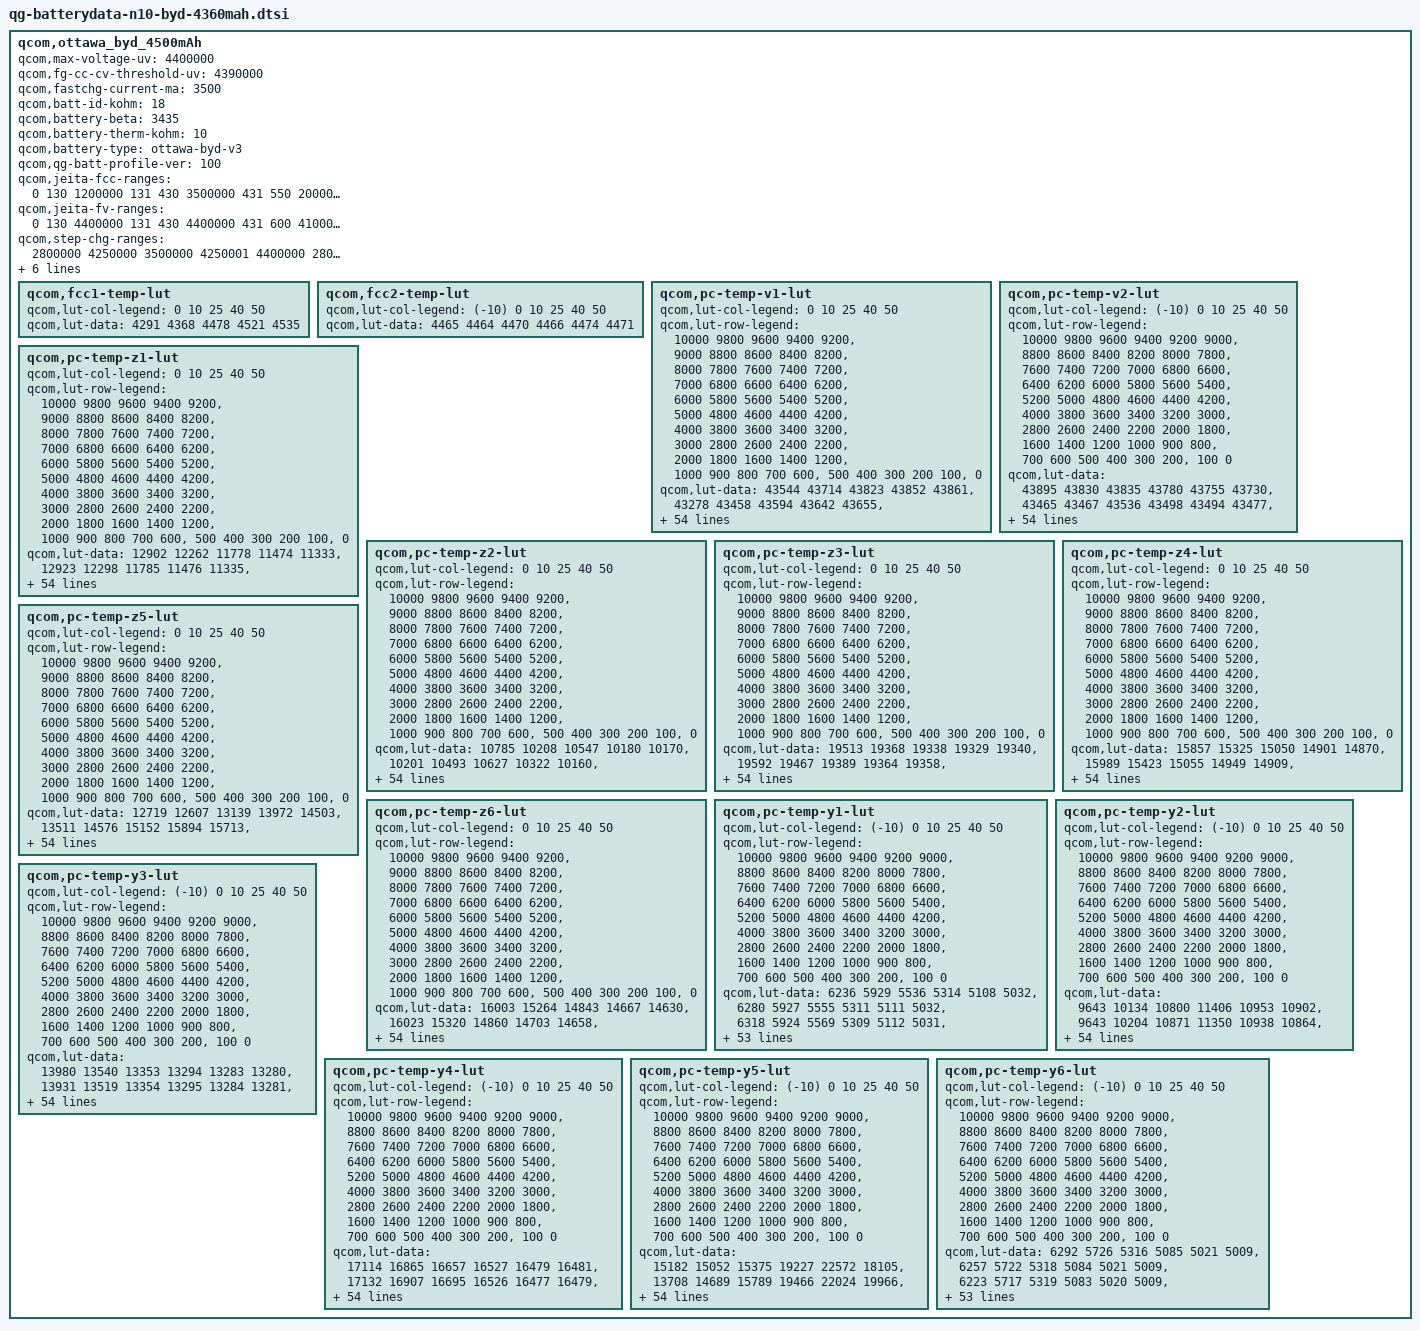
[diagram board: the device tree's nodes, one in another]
/*
 * Copyright (c) 2018, The Linux Foundation. All rights reserved.
 *
 * This program is free software; you can redistribute it and/or modify
 * it under the terms of the GNU General Public License version 2 and
 * only version 2 as published by the Free Software Foundation.
 *
 * This program is distributed in the hope that it will be useful,
 * but WITHOUT ANY WARRANTY; without even the implied warranty of
 * MERCHANTABILITY or FITNESS FOR A PARTICULAR PURPOSE.  See the
 * GNU General Public License for more details.
 */

qcom,ottawa_byd_4500mAh {
	/* 4363603_TCL_T1_Pro_4500mAH_PM6150_averaged_MasterSlave_Mar2th2020 */
	qcom,max-voltage-uv = <4400000>;
	qcom,fg-cc-cv-threshold-uv = <4390000>;
	qcom,fastchg-current-ma = <3500>;
	qcom,batt-id-kohm = <18>;
	qcom,battery-beta = <3435>;
	qcom,battery-therm-kohm = <10>;
	qcom,battery-type = "ottawa-byd-v3";
	qcom,qg-batt-profile-ver = <100>;

	qcom,jeita-fcc-ranges = <0  130   1200000
				131  430  3500000
				431 550   2000000
				551 600   0>;
	qcom,jeita-fv-ranges = <0   130   4400000
				131  430  4400000
				431  600  4100000>;
	qcom,step-chg-ranges = <2800000  4250000  3500000
				4250001  4400000  2800000>;
	qcom,ocv-based-step-chg;

	/* COOL = 10 DegC, WARM = 45 DegC */
	qcom,jeita-soft-thresholds = <0x2aee 0xfb3>;
	/* COLD = 0 DegC, HOT = 55 DegC */
	qcom,jeita-hard-thresholds = <0x3733 0xbc2>;
	/* COOL hys = 13 DegC, WARM hys = 42 DegC */
	qcom,jeita-soft-hys-thresholds = <0x279a 0x1124>;

	qcom,jeita-soft-fcc-ua = <2000000 2000000>;
	qcom,jeita-soft-fv-uv = <4100000 4100000>;

	qcom,fcc1-temp-lut {
		qcom,lut-col-legend = <0 10 25 40 50>;
		qcom,lut-data = <4291 4368 4478 4521 4535>;
	};

	qcom,fcc2-temp-lut {
		qcom,lut-col-legend = <(-10) 0 10 25 40 50>;
		qcom,lut-data = <4465 4464 4470 4466 4474 4471>;
	};

	qcom,pc-temp-v1-lut {
		qcom,lut-col-legend = <0 10 25 40 50>;
		qcom,lut-row-legend = <10000 9800 9600 9400 9200>,
			<9000 8800 8600 8400 8200>,
			<8000 7800 7600 7400 7200>,
			<7000 6800 6600 6400 6200>,
			<6000 5800 5600 5400 5200>,
			<5000 4800 4600 4400 4200>,
			<4000 3800 3600 3400 3200>,
			<3000 2800 2600 2400 2200>,
			<2000 1800 1600 1400 1200>,
			<1000 900 800 700 600>,
			<500 400 300 200 100>,
			<0>;
		qcom,lut-data = <43544 43714 43823 43852 43861>,
			<43278 43458 43594 43642 43655>,
			<43027 43209 43362 43421 43436>,
			<42788 42966 43125 43194 43213>,
			<42558 42728 42887 42959 42982>,
			<42335 42492 42648 42721 42747>,
			<42118 42263 42411 42485 42510>,
			<41906 42043 42175 42248 42272>,
			<41701 41830 41946 42014 42038>,
			<41505 41622 41720 41782 41807>,
			<41319 41418 41500 41552 41579>,
			<41130 41220 41288 41326 41353>,
			<40928 41029 41082 41104 41130>,
			<40703 40844 40881 40895 40914>,
			<40432 40634 40677 40697 40704>,
			<40136 40352 40463 40503 40501>,
			<39918 40062 40226 40303 40306>,
			<39785 39886 40006 40105 40119>,
			<39681 39782 39851 39929 39943>,
			<39573 39678 39733 39781 39789>,
			<39465 39538 39587 39621 39626>,
			<39351 39371 39347 39382 39397>,
			<39218 39179 39084 39096 39114>,
			<39072 38929 38900 38898 38912>,
			<38926 38711 38755 38774 38792>,
			<38780 38604 38643 38673 38691>,
			<38649 38535 38559 38577 38578>,
			<38552 38477 38489 38489 38467>,
			<38471 38425 38421 38404 38371>,
			<38409 38380 38356 38319 38290>,
			<38366 38339 38296 38242 38218>,
			<38332 38301 38239 38175 38154>,
			<38302 38265 38186 38115 38097>,
			<38275 38232 38137 38059 38038>,
			<38251 38200 38092 38007 37979>,
			<38224 38167 38049 37957 37920>,
			<38197 38134 38009 37909 37863>,
			<38161 38094 37968 37862 37806>,
			<38100 38030 37907 37795 37732>,
			<38018 37941 37820 37700 37630>,
			<37918 37840 37719 37593 37516>,
			<37789 37718 37607 37486 37406>,
			<37652 37578 37477 37364 37284>,
			<37504 37413 37310 37199 37119>,
			<37379 37265 37170 37066 36995>,
			<37279 37171 37075 36987 36926>,
			<37241 37145 37046 36957 36896>,
			<37212 37127 37030 36939 36877>,
			<37181 37102 37014 36919 36855>,
			<37130 37062 36969 36867 36797>,
			<36938 36861 36753 36622 36527>,
			<36510 36428 36317 36188 36091>,
			<35940 35859 35745 35616 35519>,
			<35174 35083 34971 34838 34738>,
			<33961 33854 33748 33625 33515>,
			<30000 30000 30000 30000 30000>;
	};

	qcom,pc-temp-v2-lut {
		qcom,lut-col-legend = <(-10) 0 10 25 40 50>;
		qcom,lut-row-legend = <10000 9800 9600 9400 9200 9000>,
			<8800 8600 8400 8200 8000 7800>,
			<7600 7400 7200 7000 6800 6600>,
			<6400 6200 6000 5800 5600 5400>,
			<5200 5000 4800 4600 4400 4200>,
			<4000 3800 3600 3400 3200 3000>,
			<2800 2600 2400 2200 2000 1800>,
			<1600 1400 1200 1000 900 800>,
			<700 600 500 400 300 200>,
			<100 0>;
		qcom,lut-data = <43895 43830 43835 43780 43755 43730>,
			<43465 43467 43536 43498 43494 43477>,
			<43080 43133 43252 43228 43238 43229>,
			<42748 42832 42984 42970 42990 42986>,
			<42459 42557 42733 42725 42748 42749>,
			<42198 42307 42487 42484 42508 42512>,
			<41957 42093 42240 42246 42270 42275>,
			<41736 41892 41999 42010 42033 42038>,
			<41531 41648 41772 41779 41800 41805>,
			<41333 41328 41558 41552 41570 41572>,
			<41177 41110 41350 41331 41343 41345>,
			<41089 41059 41154 41122 41124 41125>,
			<41016 41029 40960 40917 40908 40910>,
			<40821 40903 40740 40702 40699 40701>,
			<40220 40372 40482 40470 40491 40495>,
			<39670 39872 40229 40247 40292 40297>,
			<39456 39686 40013 40047 40103 40106>,
			<39313 39563 39814 39864 39924 39924>,
			<39146 39404 39619 39704 39753 39752>,
			<38945 39191 39428 39575 39600 39597>,
			<38758 38969 39236 39431 39431 39429>,
			<38606 38753 39033 39207 39202 39203>,
			<38476 38544 38831 38931 38944 38948>,
			<38377 38391 38661 38726 38748 38751>,
			<38302 38282 38520 38579 38600 38602>,
			<38237 38198 38392 38456 38475 38476>,
			<38174 38135 38266 38348 38364 38362>,
			<38115 38085 38147 38252 38264 38261>,
			<38059 38037 38055 38164 38175 38170>,
			<38007 37993 37984 38080 38095 38089>,
			<37955 37950 37929 38004 38023 38017>,
			<37902 37909 37889 37935 37959 37951>,
			<37849 37868 37858 37872 37903 37891>,
			<37793 37825 37826 37816 37839 37826>,
			<37737 37781 37794 37770 37768 37755>,
			<37678 37734 37759 37725 37692 37676>,
			<37614 37683 37721 37672 37610 37580>,
			<37545 37628 37678 37614 37525 37471>,
			<37472 37565 37623 37546 37442 37375>,
			<37393 37489 37544 37469 37364 37297>,
			<37312 37399 37446 37381 37282 37220>,
			<37236 37288 37329 37278 37186 37125>,
			<37164 37160 37190 37157 37074 37011>,
			<37095 37039 37038 37027 36948 36887>,
			<37027 36933 36904 36912 36845 36791>,
			<36950 36864 36836 36856 36801 36749>,
			<36904 36834 36813 36836 36790 36737>,
			<36847 36798 36788 36817 36772 36720>,
			<36771 36750 36747 36789 36742 36688>,
			<36657 36651 36667 36718 36655 36586>,
			<36429 36417 36439 36458 36338 36238>,
			<36030 35978 35970 35987 35840 35737>,
			<35442 35346 35332 35368 35192 35073>,
			<34582 34448 34451 34531 34306 34168>,
			<33177 33014 33092 33262 33030 32907>,
			<28802 27992 27897 27933 28022 27983>;
	};

	qcom,pc-temp-z1-lut {
		qcom,lut-col-legend = <0 10 25 40 50>;
		qcom,lut-row-legend = <10000 9800 9600 9400 9200>,
			<9000 8800 8600 8400 8200>,
			<8000 7800 7600 7400 7200>,
			<7000 6800 6600 6400 6200>,
			<6000 5800 5600 5400 5200>,
			<5000 4800 4600 4400 4200>,
			<4000 3800 3600 3400 3200>,
			<3000 2800 2600 2400 2200>,
			<2000 1800 1600 1400 1200>,
			<1000 900 800 700 600>,
			<500 400 300 200 100>,
			<0>;
		qcom,lut-data = <12902 12262 11778 11474 11333>,
			<12923 12298 11785 11476 11335>,
			<12915 12291 11783 11470 11331>,
			<12899 12278 11772 11461 11325>,
			<12880 12267 11758 11447 11315>,
			<12864 12248 11747 11433 11306>,
			<12853 12225 11736 11421 11298>,
			<12841 12207 11724 11409 11291>,
			<12834 12192 11711 11400 11285>,
			<12833 12184 11698 11393 11282>,
			<12834 12180 11692 11389 11280>,
			<12831 12177 11692 11390 11278>,
			<12802 12165 11691 11391 11277>,
			<12754 12139 11686 11391 11275>,
			<12709 12124 11673 11382 11274>,
			<12669 12124 11666 11374 11273>,
			<12654 12126 11665 11373 11273>,
			<12666 12126 11666 11374 11274>,
			<12688 12132 11667 11376 11275>,
			<12702 12140 11674 11379 11276>,
			<12710 12147 11680 11381 11277>,
			<12718 12156 11685 11383 11278>,
			<12733 12159 11690 11385 11278>,
			<12751 12157 11694 11387 11280>,
			<12756 12156 11699 11390 11281>,
			<12750 12163 11703 11392 11283>,
			<12744 12177 11708 11396 11286>,
			<12748 12183 11712 11401 11290>,
			<12761 12182 11719 11406 11294>,
			<12769 12179 11726 11411 11297>,
			<12768 12181 11732 11417 11301>,
			<12767 12191 11737 11422 11306>,
			<12772 12197 11740 11428 11310>,
			<12787 12199 11744 11434 11316>,
			<12804 12201 11748 11440 11321>,
			<12814 12206 11752 11447 11327>,
			<12825 12216 11759 11454 11332>,
			<12833 12226 11767 11461 11337>,
			<12838 12233 11774 11467 11343>,
			<12842 12240 11780 11473 11348>,
			<12850 12248 11785 11479 11353>,
			<12872 12257 11792 11488 11359>,
			<12900 12267 11801 11498 11364>,
			<12933 12277 11819 11502 11368>,
			<12953 12303 11826 11507 11373>,
			<12941 12312 11825 11512 11375>,
			<12936 12307 11822 11515 11374>,
			<12943 12311 11835 11516 11375>,
			<12917 12310 11834 11520 11379>,
			<12922 12311 11829 11529 11386>,
			<12945 12325 11850 11536 11395>,
			<12969 12340 11861 11543 11403>,
			<13024 12377 11867 11559 11414>,
			<13078 12420 11901 11579 11428>,
			<13078 12420 11901 11579 11428>,
			<13078 12420 11901 11579 11428>;
	};

	qcom,pc-temp-z2-lut {
		qcom,lut-col-legend = <0 10 25 40 50>;
		qcom,lut-row-legend = <10000 9800 9600 9400 9200>,
			<9000 8800 8600 8400 8200>,
			<8000 7800 7600 7400 7200>,
			<7000 6800 6600 6400 6200>,
			<6000 5800 5600 5400 5200>,
			<5000 4800 4600 4400 4200>,
			<4000 3800 3600 3400 3200>,
			<3000 2800 2600 2400 2200>,
			<2000 1800 1600 1400 1200>,
			<1000 900 800 700 600>,
			<500 400 300 200 100>,
			<0>;
		qcom,lut-data = <10785 10208 10547 10180 10170>,
			<10201 10493 10627 10322 10160>,
			<10245 10526 10660 10413 10269>,
			<10269 10518 10640 10439 10308>,
			<10270 10499 10567 10409 10274>,
			<10272 10458 10499 10370 10233>,
			<10281 10416 10453 10332 10216>,
			<10288 10387 10416 10282 10201>,
			<10292 10363 10390 10245 10179>,
			<10288 10347 10372 10229 10131>,
			<10276 10335 10367 10226 10080>,
			<10284 10328 10374 10240 10045>,
			<10342 10427 10379 10258 10014>,
			<10375 10815 10378 10253 10002>,
			<10324 11057 10390 10177 10018>,
			<10243 10853 10401 10105 10042>,
			<10213 10517 10400 10098 10059>,
			<10205 10430 10392 10101 10075>,
			<10197 10431 10387 10108 10090>,
			<10195 10435 10394 10130 10103>,
			<10203 10471 10421 10169 10120>,
			<10215 10535 10554 10321 10202>,
			<10239 10556 10695 10556 10340>,
			<10277 10543 10669 10588 10365>,
			<10307 10529 10527 10361 10270>,
			<10327 10538 10454 10182 10194>,
			<10344 10567 10457 10188 10428>,
			<10359 10584 10463 10226 10977>,
			<10374 10587 10481 10296 11141>,
			<10386 10587 10525 10494 10874>,
			<10391 10588 10566 10641 10543>,
			<10395 10594 10605 10595 10307>,
			<10396 10600 10640 10476 10106>,
			<10398 10605 10643 10378 10052>,
			<10400 10610 10626 10288 10049>,
			<10405 10617 10616 10239 10049>,
			<10415 10624 10620 10244 10073>,
			<10427 10634 10632 10261 10133>,
			<10446 10654 10658 10296 10192>,
			<10465 10683 10723 10396 10257>,
			<10471 10697 10761 10465 10298>,
			<10472 10697 10750 10427 10304>,
			<10417 10696 10740 10381 10309>,
			<10193 10696 10747 10494 10367>,
			<11963 10818 10738 10486 10352>,
			<11905 10826 10747 10403 10281>,
			<12046 10807 10722 10400 10260>,
			<12088 10820 10692 10416 10278>,
			<11990 10816 10639 10419 10297>,
			<12129 10877 10680 10504 10406>,
			<11455 10917 10705 10450 10302>,
			<10891 10899 10678 10275 10092>,
			<10730 10690 10632 10206 10033>,
			<9900 10598 10515 10168 9987>,
			<9900 10598 10515 10168 9987>,
			<9900 10598 10515 10168 9987>;
	};

	qcom,pc-temp-z3-lut {
		qcom,lut-col-legend = <0 10 25 40 50>;
		qcom,lut-row-legend = <10000 9800 9600 9400 9200>,
			<9000 8800 8600 8400 8200>,
			<8000 7800 7600 7400 7200>,
			<7000 6800 6600 6400 6200>,
			<6000 5800 5600 5400 5200>,
			<5000 4800 4600 4400 4200>,
			<4000 3800 3600 3400 3200>,
			<3000 2800 2600 2400 2200>,
			<2000 1800 1600 1400 1200>,
			<1000 900 800 700 600>,
			<500 400 300 200 100>,
			<0>;
		qcom,lut-data = <19513 19368 19338 19329 19340>,
			<19592 19467 19389 19364 19358>,
			<19657 19508 19423 19389 19379>,
			<19687 19531 19435 19404 19392>,
			<19690 19540 19441 19413 19401>,
			<19685 19543 19444 19419 19406>,
			<19678 19545 19447 19422 19411>,
			<19668 19543 19448 19424 19414>,
			<19657 19538 19448 19424 19415>,
			<19644 19533 19446 19419 19410>,
			<19630 19528 19443 19414 19403>,
			<19626 19523 19439 19411 19398>,
			<19626 19521 19434 19409 19396>,
			<19627 19520 19426 19404 19393>,
			<19627 19519 19415 19393 19389>,
			<19628 19513 19411 19384 19385>,
			<19626 19500 19414 19380 19381>,
			<19612 19487 19416 19378 19377>,
			<19588 19470 19410 19374 19373>,
			<19574 19459 19397 19367 19365>,
			<19565 19461 19392 19363 19360>,
			<19561 19467 19401 19368 19361>,
			<19566 19471 19412 19379 19365>,
			<19578 19473 19410 19379 19365>,
			<19586 19474 19398 19360 19348>,
			<19588 19474 19390 19344 19331>,
			<19589 19473 19388 19345 19356>,
			<19589 19472 19386 19348 19416>,
			<19588 19472 19387 19356 19436>,
			<19586 19472 19392 19383 19430>,
			<19582 19471 19397 19404 19420>,
			<19576 19470 19405 19404 19409>,
			<19571 19470 19414 19401 19397>,
			<19566 19469 19415 19397 19387>,
			<19561 19469 19414 19390 19378>,
			<19554 19467 19412 19381 19371>,
			<19547 19464 19406 19372 19362>,
			<19541 19460 19399 19364 19355>,
			<19538 19457 19395 19362 19352>,
			<19535 19453 19393 19362 19351>,
			<19532 19449 19391 19362 19350>,
			<19527 19446 19386 19360 19353>,
			<19500 19442 19382 19358 19358>,
			<19402 19437 19381 19364 19365>,
			<19285 19420 19372 19362 19363>,
			<19259 19411 19365 19346 19348>,
			<19259 19405 19365 19343 19344>,
			<19258 19392 19359 19336 19333>,
			<19258 19386 19348 19330 19329>,
			<19258 19362 19343 19326 19315>,
			<19259 19382 19345 19344 19339>,
			<19259 19370 19364 19364 19361>,
			<19261 19345 19369 19365 19360>,
			<19265 19341 19349 19357 19357>,
			<19265 19341 19349 19357 19357>,
			<19265 19341 19349 19357 19357>;
	};

	qcom,pc-temp-z4-lut {
		qcom,lut-col-legend = <0 10 25 40 50>;
		qcom,lut-row-legend = <10000 9800 9600 9400 9200>,
			<9000 8800 8600 8400 8200>,
			<8000 7800 7600 7400 7200>,
			<7000 6800 6600 6400 6200>,
			<6000 5800 5600 5400 5200>,
			<5000 4800 4600 4400 4200>,
			<4000 3800 3600 3400 3200>,
			<3000 2800 2600 2400 2200>,
			<2000 1800 1600 1400 1200>,
			<1000 900 800 700 600>,
			<500 400 300 200 100>,
			<0>;
		qcom,lut-data = <15857 15325 15050 14901 14870>,
			<15989 15423 15055 14949 14909>,
			<15829 15360 15048 14926 14896>,
			<15639 15210 15015 14897 14877>,
			<15485 15092 14947 14863 14852>,
			<15352 15010 14889 14828 14823>,
			<15249 14943 14849 14799 14798>,
			<15167 14891 14815 14774 14774>,
			<15104 14848 14785 14754 14756>,
			<15055 14817 14759 14739 14744>,
			<15012 14796 14744 14728 14736>,
			<14958 14777 14737 14722 14730>,
			<14889 14743 14732 14718 14725>,
			<14841 14691 14724 14714 14720>,
			<14833 14666 14714 14708 14715>,
			<14838 14699 14709 14705 14710>,
			<14832 14751 14710 14703 14706>,
			<14812 14757 14711 14701 14703>,
			<14789 14727 14704 14696 14698>,
			<14772 14703 14685 14683 14688>,
			<14754 14705 14677 14673 14680>,
			<14742 14713 14722 14708 14711>,
			<14741 14732 14793 14792 14797>,
			<14743 14811 14833 14835 14841>,
			<14748 14884 14861 14850 14849>,
			<14774 14885 14871 14857 14853>,
			<14802 14869 14861 14849 14820>,
			<14809 14852 14842 14828 14740>,
			<14813 14835 14825 14801 14707>,
			<14815 14816 14807 14759 14703>,
			<14809 14800 14788 14725 14700>,
			<14797 14785 14768 14712 14696>,
			<14785 14772 14750 14703 14692>,
			<14774 14760 14740 14700 14688>,
			<14763 14750 14734 14699 14685>,
			<14752 14741 14730 14698 14683>,
			<14742 14731 14727 14697 14683>,
			<14733 14726 14725 14696 14682>,
			<14725 14727 14726 14698 14685>,
			<14719 14727 14730 14710 14703>,
			<14718 14727 14733 14719 14717>,
			<14719 14722 14726 14714 14710>,
			<14740 14715 14717 14707 14700>,
			<14829 14708 14714 14705 14705>,
			<14884 14683 14695 14693 14694>,
			<14893 14672 14675 14678 14673>,
			<14889 14666 14668 14673 14670>,
			<14880 14664 14657 14661 14662>,
			<14873 14659 14649 14644 14640>,
			<14867 14680 14644 14633 14635>,
			<14870 14667 14662 14655 14666>,
			<14893 14697 14659 14657 14670>,
			<14904 14732 14657 14662 14679>,
			<14919 14744 14681 14673 14685>,
			<14919 14744 14681 14673 14685>,
			<14919 14744 14681 14673 14685>;
	};

	qcom,pc-temp-z5-lut {
		qcom,lut-col-legend = <0 10 25 40 50>;
		qcom,lut-row-legend = <10000 9800 9600 9400 9200>,
			<9000 8800 8600 8400 8200>,
			<8000 7800 7600 7400 7200>,
			<7000 6800 6600 6400 6200>,
			<6000 5800 5600 5400 5200>,
			<5000 4800 4600 4400 4200>,
			<4000 3800 3600 3400 3200>,
			<3000 2800 2600 2400 2200>,
			<2000 1800 1600 1400 1200>,
			<1000 900 800 700 600>,
			<500 400 300 200 100>,
			<0>;
		qcom,lut-data = <12719 12607 13139 13972 14503>,
			<13511 14576 15152 15894 15713>,
			<14310 15773 16609 17425 17678>,
			<14907 16652 17361 18530 19028>,
			<15225 17538 17813 19343 19864>,
			<15510 18475 18335 20137 20647>,
			<15924 19419 19053 21112 21893>,
			<16420 20326 19934 22160 23585>,
			<16837 21205 20999 23131 24607>,
			<17133 22209 22293 24033 24905>,
			<17443 23342 23446 24938 25139>,
			<18018 24772 24367 26040 25576>,
			<19153 27408 24990 27170 26366>,
			<20590 32133 24981 27303 27318>,
			<22325 34811 24886 25792 28431>,
			<24361 33005 25334 24499 29586>,
			<25238 29603 26351 24570 30758>,
			<24126 27959 27203 25139 32157>,
			<22591 27229 27852 25820 33360>,
			<22278 26912 29675 27505 34315>,
			<23001 32282 32788 30117 35107>,
			<24474 43306 40752 34280 35601>,
			<29828 47301 48491 38950 35514>,
			<39947 47289 46086 38714 33923>,
			<46812 46996 34270 28326 25155>,
			<50265 44986 26304 19201 17432>,
			<52306 40162 23688 17777 21801>,
			<52186 36899 22203 17134 32820>,
			<50928 35287 22150 17486 36845>,
			<49414 34278 22675 21492 36574>,
			<47382 34242 23516 26105 35828>,
			<44704 34722 26089 29040 34271>,
			<42579 35455 30065 31418 31806>,
			<40980 37045 33668 32702 31104>,
			<39583 39294 37441 33529 31717>,
			<38169 41010 39152 33908 32221>,
			<36756 42548 38854 33371 32000>,
			<36201 43392 38185 32186 31362>,
			<37741 43161 37368 31636 30644>,
			<39748 42428 36180 31493 29707>,
			<39929 41357 34561 31276 28726>,
			<38616 38915 31101 28219 27657>,
			<35116 36981 28673 24900 26942>,
			<25434 35927 28872 28193 30650>,
			<14423 38239 29033 28519 31130>,
			<11781 35678 29040 22616 23835>,
			<11695 32125 29349 21734 21488>,
			<11625 26422 27917 20974 19411>,
			<11607 26031 24954 22608 22482>,
			<11604 20276 24866 24339 20631>,
			<11694 23343 21915 27100 25005>,
			<11661 18332 23795 25747 22814>,
			<11563 14961 24455 23181 19574>,
			<11452 14193 17490 18431 16639>,
			<11452 14193 17490 18431 16639>,
			<11452 14193 17490 18431 16639>;
	};

	qcom,pc-temp-z6-lut {
		qcom,lut-col-legend = <0 10 25 40 50>;
		qcom,lut-row-legend = <10000 9800 9600 9400 9200>,
			<9000 8800 8600 8400 8200>,
			<8000 7800 7600 7400 7200>,
			<7000 6800 6600 6400 6200>,
			<6000 5800 5600 5400 5200>,
			<5000 4800 4600 4400 4200>,
			<4000 3800 3600 3400 3200>,
			<3000 2800 2600 2400 2200>,
			<2000 1800 1600 1400 1200>,
			<1000 900 800 700 600>,
			<500 400 300 200 100>,
			<0>;
		qcom,lut-data = <16003 15264 14843 14667 14630>,
			<16023 15320 14860 14703 14658>,
			<15926 15288 14865 14704 14661>,
			<15806 15208 14854 14700 14660>,
			<15701 15140 14820 14687 14653>,
			<15605 15087 14788 14673 14643>,
			<15527 15041 14766 14661 14634>,
			<15463 15002 14747 14649 14625>,
			<15408 14969 14730 14638 14617>,
			<15363 14943 14715 14628 14608>,
			<15324 14923 14704 14619 14600>,
			<15280 14905 14699 14615 14594>,
			<15226 14881 14694 14612 14590>,
			<15183 14851 14684 14608 14586>,
			<15163 14837 14670 14597 14581>,
			<15150 14844 14664 14589 14576>,
			<15137 14853 14665 14586 14572>,
			<15120 14852 14666 14584 14568>,
			<15105 14833 14661 14580 14563>,
			<15097 14819 14648 14570 14555>,
			<15091 14821 14643 14564 14548>,
			<15088 14830 14669 14584 14563>,
			<15092 14846 14707 14627 14603>,
			<15103 14883 14721 14641 14619>,
			<15117 14915 14729 14639 14615>,
			<15134 14916 14731 14636 14609>,
			<15148 14912 14727 14632 14608>,
			<15153 14906 14720 14626 14607>,
			<15157 14900 14715 14622 14606>,
			<15159 14894 14711 14619 14601>,
			<15156 14888 14707 14616 14595>,
			<15151 14884 14705 14612 14588>,
			<15147 14880 14703 14608 14581>,
			<15144 14877 14701 14604 14574>,
			<15140 14874 14700 14601 14569>,
			<15137 14872 14698 14598 14565>,
			<15134 14870 14696 14593 14561>,
			<15132 14869 14693 14589 14557>,
			<15135 14871 14693 14589 14557>,
			<15141 14875 14698 14595 14564>,
			<15147 14878 14700 14599 14570>,
			<15156 14880 14698 14597 14569>,
			<15161 14882 14695 14595 14568>,
			<15165 14884 14696 14599 14574>,
			<15153 14877 14689 14594 14570>,
			<15148 14872 14680 14580 14554>,
			<15146 14866 14677 14577 14550>,
			<15145 14858 14669 14568 14541>,
			<15144 14855 14661 14558 14530>,
			<15147 14855 14660 14552 14521>,
			<15160 14870 14673 14573 14548>,
			<15181 14885 14687 14589 14565>,
			<15201 14895 14694 14595 14572>,
			<15231 14914 14702 14600 14577>,
			<15231 14914 14702 14600 14577>,
			<15231 14914 14702 14600 14577>;
	};

	qcom,pc-temp-y1-lut {
		qcom,lut-col-legend = <(-10) 0 10 25 40 50>;
		qcom,lut-row-legend = <10000 9800 9600 9400 9200 9000>,
			<8800 8600 8400 8200 8000 7800>,
			<7600 7400 7200 7000 6800 6600>,
			<6400 6200 6000 5800 5600 5400>,
			<5200 5000 4800 4600 4400 4200>,
			<4000 3800 3600 3400 3200 3000>,
			<2800 2600 2400 2200 2000 1800>,
			<1600 1400 1200 1000 900 800>,
			<700 600 500 400 300 200>,
			<100 0>;
		qcom,lut-data = <6236 5929 5536 5314 5108 5032>,
			<6280 5927 5555 5311 5111 5032>,
			<6318 5924 5569 5309 5112 5031>,
			<6347 5921 5578 5306 5112 5029>,
			<6367 5917 5583 5303 5110 5028>,
			<6374 5913 5584 5300 5109 5026>,
			<6365 5907 5577 5296 5106 5024>,
			<6349 5902 5568 5290 5102 5021>,
			<6345 5901 5566 5287 5099 5019>,
			<6349 5907 5568 5284 5096 5018>,
			<6353 5912 5569 5283 5093 5016>,
			<6354 5916 5568 5282 5091 5015>,
			<6354 5920 5566 5282 5090 5013>,
			<6356 5923 5565 5282 5088 5013>,
			<6370 5926 5566 5281 5084 5012>,
			<6384 5929 5567 5280 5081 5012>,
			<6387 5933 5573 5281 5083 5012>,
			<6384 5937 5582 5285 5087 5013>,
			<6382 5937 5586 5287 5088 5013>,
			<6384 5937 5588 5289 5087 5014>,
			<6386 5936 5590 5290 5086 5014>,
			<6386 5936 5588 5291 5087 5015>,
			<6388 5938 5585 5292 5090 5015>,
			<6391 5940 5585 5294 5093 5016>,
			<6379 5939 5589 5301 5095 5017>,
			<6364 5937 5592 5307 5097 5019>,
			<6363 5935 5589 5309 5101 5022>,
			<6367 5933 5585 5310 5105 5024>,
			<6367 5931 5584 5312 5109 5027>,
			<6354 5931 5591 5315 5113 5031>,
			<6340 5930 5597 5319 5118 5034>,
			<6340 5928 5597 5323 5123 5038>,
			<6344 5926 5595 5328 5127 5041>,
			<6347 5925 5594 5333 5132 5044>,
			<6340 5923 5597 5336 5135 5046>,
			<6332 5922 5600 5339 5138 5048>,
			<6328 5924 5602 5342 5142 5051>,
			<6326 5926 5603 5348 5145 5055>,
			<6326 5926 5603 5353 5148 5057>,
			<6332 5921 5600 5355 5151 5059>,
			<6339 5918 5598 5358 5154 5060>,
			<6338 5920 5602 5361 5156 5061>,
			<6335 5925 5607 5370 5159 5063>,
			<6333 5929 5605 5380 5166 5068>,
			<6331 5931 5602 5390 5176 5075>,
			<6385 5952 5610 5396 5187 5076>,
			<6399 5953 5634 5393 5183 5075>,
			<6402 5952 5647 5384 5178 5074>,
			<6400 5972 5628 5392 5173 5075>,
			<6399 5966 5796 5395 5174 5076>,
			<6411 5963 5638 5386 5179 5078>,
			<6437 5983 5649 5399 5186 5084>,
			<6436 6001 5661 5425 5201 5091>,
			<6507 6048 5677 5436 5211 5101>,
			<6507 6048 5677 5436 5211 5101>,
			<6507 6048 5677 5436 5211 5101>;
	};

	qcom,pc-temp-y2-lut {
		qcom,lut-col-legend = <(-10) 0 10 25 40 50>;
		qcom,lut-row-legend = <10000 9800 9600 9400 9200 9000>,
			<8800 8600 8400 8200 8000 7800>,
			<7600 7400 7200 7000 6800 6600>,
			<6400 6200 6000 5800 5600 5400>,
			<5200 5000 4800 4600 4400 4200>,
			<4000 3800 3600 3400 3200 3000>,
			<2800 2600 2400 2200 2000 1800>,
			<1600 1400 1200 1000 900 800>,
			<700 600 500 400 300 200>,
			<100 0>;
		qcom,lut-data = <9643 10134 10800 11406 10953 10902>,
			<9643 10204 10871 11350 10938 10864>,
			<9644 10263 10919 11296 10918 10827>,
			<9714 10308 10950 11244 10895 10792>,
			<9794 10338 10966 11195 10870 10760>,
			<9880 10351 10971 11151 10844 10733>,
			<9999 10342 10961 11109 10813 10710>,
			<10107 10328 10936 11070 10783 10690>,
			<10079 10429 10891 11042 10765 10676>,
			<9834 11025 10778 11023 10750 10665>,
			<9674 11472 10702 11003 10741 10657>,
			<9675 11201 10869 10971 10740 10649>,
			<9676 10677 11172 10939 10739 10642>,
			<9676 10554 11249 10942 10744 10643>,
			<9673 10734 11227 11025 10770 10660>,
			<9670 10942 11208 11126 10806 10674>,
			<9670 11098 11269 11199 10855 10670>,
			<9670 11227 11390 11275 10922 10662>,
			<9669 11168 11436 11376 11004 10683>,
			<9669 10441 11442 11534 11129 10856>,
			<9668 9800 11440 11638 11210 10993>,
			<9668 9723 11431 11566 11152 10979>,
			<9668 9697 11418 11412 11039 10948>,
			<9667 9692 11414 11365 11009 10937>,
			<9667 9693 11414 11390 11038 10928>,
			<9666 9693 11412 11428 11075 10920>,
			<9665 9690 11388 11467 11112 10931>,
			<9665 9684 11341 11511 11156 10969>,
			<9665 9679 11320 11553 11184 11011>,
			<9664 9676 11322 11600 11220 11074>,
			<9664 9674 11322 11629 11267 11127>,
			<9663 9671 11308 11628 11338 11147>,
			<9663 9669 11281 11622 11420 11160>,
			<9663 9667 11246 11612 11442 11184>,
			<9662 9666 11192 11589 11405 11236>,
			<9662 9665 11127 11556 11353 11275>,
			<9662 9664 11067 11521 11318 11243>,
			<9661 9663 11000 11480 11288 11140>,
			<9661 9662 10849 11442 11252 11069>,
			<9661 9661 10313 11409 11198 11044>,
			<9661 9661 9811 11376 11160 11042>,
			<9660 9660 9719 11335 11166 11053>,
			<9660 9660 9695 11285 11176 11026>,
			<9660 9659 9685 11207 11083 10909>,
			<9659 9659 9678 11089 10968 10777>,
			<9659 9658 9675 11063 10922 10745>,
			<9659 9658 9676 11067 10982 10759>,
			<9659 9658 9673 11070 11030 10808>,
			<9658 9658 9669 11105 11087 10847>,
			<9657 9657 9668 11099 11089 10872>,
			<9657 9657 9666 10998 11006 10726>,
			<9657 9656 9663 10876 10870 10649>,
			<9656 9656 9660 10786 10813 10557>,
			<9653 9655 9658 10748 10728 10499>,
			<9653 9655 9658 10748 10728 10499>,
			<9653 9655 9658 10748 10728 10499>;
	};

	qcom,pc-temp-y3-lut {
		qcom,lut-col-legend = <(-10) 0 10 25 40 50>;
		qcom,lut-row-legend = <10000 9800 9600 9400 9200 9000>,
			<8800 8600 8400 8200 8000 7800>,
			<7600 7400 7200 7000 6800 6600>,
			<6400 6200 6000 5800 5600 5400>,
			<5200 5000 4800 4600 4400 4200>,
			<4000 3800 3600 3400 3200 3000>,
			<2800 2600 2400 2200 2000 1800>,
			<1600 1400 1200 1000 900 800>,
			<700 600 500 400 300 200>,
			<100 0>;
		qcom,lut-data = <13980 13540 13353 13294 13283 13280>,
			<13931 13519 13354 13295 13284 13281>,
			<13863 13507 13355 13296 13284 13282>,
			<13793 13501 13356 13298 13285 13283>,
			<13735 13500 13358 13299 13286 13284>,
			<13702 13501 13359 13300 13286 13284>,
			<13692 13512 13361 13301 13286 13285>,
			<13685 13530 13363 13301 13287 13286>,
			<13657 13520 13366 13302 13287 13286>,
			<13564 13435 13373 13303 13288 13286>,
			<13500 13373 13377 13304 13288 13287>,
			<13511 13379 13372 13306 13289 13288>,
			<13533 13390 13361 13308 13292 13290>,
			<13534 13393 13354 13309 13293 13292>,
			<13504 13393 13345 13309 13294 13292>,
			<13481 13392 13339 13309 13295 13293>,
			<13487 13387 13338 13306 13297 13293>,
			<13500 13376 13338 13302 13298 13293>,
			<13504 13371 13337 13301 13298 13293>,
			<13501 13372 13331 13302 13296 13293>,
			<13498 13373 13325 13302 13293 13293>,
			<13498 13366 13320 13300 13288 13289>,
			<13500 13349 13316 13293 13284 13283>,
			<13503 13336 13312 13290 13282 13280>,
			<13518 13326 13309 13288 13282 13280>,
			<13537 13321 13306 13288 13281 13280>,
			<13554 13328 13304 13287 13280 13279>,
			<13573 13347 13302 13287 13279 13279>,
			<13593 13366 13300 13287 13279 13279>,
			<13618 13384 13299 13286 13278 13279>,
			<13644 13404 13298 13286 13278 13280>,
			<13669 13426 13299 13285 13279 13279>,
			<13696 13452 13303 13285 13281 13279>,
			<13725 13481 13306 13285 13281 13279>,
			<13754 13511 13308 13286 13281 13280>,
			<13784 13543 13310 13287 13281 13282>,
			<13813 13579 13312 13287 13281 13281>,
			<13843 13619 13315 13288 13281 13280>,
			<13873 13661 13321 13289 13281 13280>,
			<13903 13704 13335 13290 13281 13282>,
			<13935 13747 13349 13290 13282 13283>,
			<13973 13787 13353 13292 13284 13284>,
			<14018 13826 13353 13294 13285 13283>,
			<14068 13868 13369 13294 13283 13282>,
			<14128 13917 13402 13295 13283 13283>,
			<14165 13959 13429 13301 13290 13289>,
			<14183 13975 13428 13301 13294 13291>,
			<14229 14009 13452 13306 13296 13293>,
			<14297 14063 13484 13313 13297 13294>,
			<14380 14117 13522 13318 13297 13293>,
			<14459 14161 13563 13314 13293 13289>,
			<14559 14232 13619 13316 13293 13291>,
			<14713 14351 13751 13324 13300 13296>,
			<15199 14492 13933 13336 13310 13308>,
			<15199 14492 13933 13336 13310 13308>,
			<15199 14492 13933 13336 13310 13308>;
	};

	qcom,pc-temp-y4-lut {
		qcom,lut-col-legend = <(-10) 0 10 25 40 50>;
		qcom,lut-row-legend = <10000 9800 9600 9400 9200 9000>,
			<8800 8600 8400 8200 8000 7800>,
			<7600 7400 7200 7000 6800 6600>,
			<6400 6200 6000 5800 5600 5400>,
			<5200 5000 4800 4600 4400 4200>,
			<4000 3800 3600 3400 3200 3000>,
			<2800 2600 2400 2200 2000 1800>,
			<1600 1400 1200 1000 900 800>,
			<700 600 500 400 300 200>,
			<100 0>;
		qcom,lut-data = <17114 16865 16657 16527 16479 16481>,
			<17132 16907 16695 16526 16477 16479>,
			<17148 16953 16730 16525 16475 16477>,
			<17159 16995 16759 16524 16473 16475>,
			<17164 17027 16779 16523 16472 16473>,
			<17162 17040 16786 16522 16471 16472>,
			<17131 17032 16780 16521 16471 16471>,
			<17089 17019 16767 16519 16471 16470>,
			<17119 17030 16759 16519 16472 16469>,
			<17358 17122 16752 16522 16475 16470>,
			<17552 17241 16748 16525 16478 16471>,
			<17596 17381 16790 16528 16480 16472>,
			<17622 17526 16867 16530 16482 16474>,
			<17572 17508 16890 16535 16486 16477>,
			<17185 17131 16876 16546 16493 16481>,
			<16867 16836 16859 16561 16502 16486>,
			<16838 16844 16840 16582 16510 16491>,
			<16827 16878 16812 16610 16520 16500>,
			<16804 16883 16790 16637 16537 16514>,
			<16752 16836 16768 16667 16576 16546>,
			<16702 16769 16741 16684 16603 16568>,
			<16674 16697 16692 16641 16573 16548>,
			<16655 16623 16630 16545 16510 16502>,
			<16650 16600 16594 16503 16480 16478>,
			<16649 16603 16576 16490 16468 16467>,
			<16649 16607 16560 16485 16463 16461>,
			<16652 16605 16534 16486 16465 16462>,
			<16658 16599 16503 16490 16470 16465>,
			<16663 16598 16491 16493 16476 16470>,
			<16666 16603 16490 16496 16486 16477>,
			<16670 16610 16492 16498 16496 16486>,
			<16674 16617 16499 16498 16506 16499>,
			<16680 16625 16513 16497 16515 16514>,
			<16684 16634 16529 16497 16517 16519>,
			<16689 16647 16548 16501 16512 16518>,
			<16692 16661 16568 16505 16504 16516>,
			<16694 16668 16589 16506 16493 16505>,
			<16695 16672 16609 16507 16479 16482>,
			<16696 16673 16624 16508 16475 16474>,
			<16694 16674 16634 16512 16481 16482>,
			<16691 16675 16642 16518 16488 16492>,
			<16695 16667 16647 16527 16490 16495>,
			<16708 16651 16650 16536 16488 16490>,
			<16730 16641 16640 16541 16478 16470>,
			<16763 16639 16633 16548 16474 16462>,
			<16768 16647 16637 16553 16493 16499>,
			<16765 16658 16641 16552 16513 16530>,
			<16779 16680 16660 16574 16547 16564>,
			<16808 16720 16694 16609 16581 16597>,
			<16826 16751 16730 16645 16596 16590>,
			<16823 16757 16738 16608 16514 16499>,
			<16805 16746 16716 16596 16501 16490>,
			<16802 16746 16725 16617 16512 16490>,
			<16939 16771 16752 16659 16544 16510>,
			<16939 16771 16752 16659 16544 16510>,
			<16939 16771 16752 16659 16544 16510>;
	};

	qcom,pc-temp-y5-lut {
		qcom,lut-col-legend = <(-10) 0 10 25 40 50>;
		qcom,lut-row-legend = <10000 9800 9600 9400 9200 9000>,
			<8800 8600 8400 8200 8000 7800>,
			<7600 7400 7200 7000 6800 6600>,
			<6400 6200 6000 5800 5600 5400>,
			<5200 5000 4800 4600 4400 4200>,
			<4000 3800 3600 3400 3200 3000>,
			<2800 2600 2400 2200 2000 1800>,
			<1600 1400 1200 1000 900 800>,
			<700 600 500 400 300 200>,
			<100 0>;
		qcom,lut-data = <15182 15052 15375 19227 22572 18105>,
			<13708 14689 15789 19466 22024 19966>,
			<13231 14679 16271 19522 21392 21158>,
			<13493 14958 16748 19457 20757 21840>,
			<14238 15466 17151 19332 20195 22171>,
			<15210 16141 17405 19208 19786 22311>,
			<17107 17754 17505 18952 19233 21984>,
			<19219 19705 17579 18511 18458 21297>,
			<18966 19421 17924 18128 17757 20763>,
			<15486 15128 19378 17717 16850 19517>,
			<13162 11987 20429 17263 16324 18632>,
			<15858 14116 18321 16618 16516 18868>,
			<20727 18065 14482 15952 16886 19289>,
			<21402 19154 13796 15812 16935 19289>,
			<17261 19108 16132 15909 16586 18510>,
			<14014 19097 18519 15985 16186 17533>,
			<14973 20026 19516 15501 15844 16590>,
			<17090 21707 20261 14577 15525 15709>,
			<17685 22179 21083 14599 15435 15420>,
			<17039 21960 22121 17006 15446 15318>,
			<16088 21569 23018 19703 15494 15287>,
			<14906 20432 23553 21321 17083 16683>,
			<13636 18012 23948 22584 20030 19522>,
			<13294 15823 24288 22855 20936 20573>,
			<13302 13765 24643 22502 20899 20735>,
			<13308 12565 24903 22199 20716 20786>,
			<13257 12691 24858 22273 19688 19741>,
			<13135 13142 24377 22452 17752 17656>,
			<13133 13452 23427 22514 16990 16867>,
			<13420 13603 20603 22450 16863 16673>,
			<13699 13753 18473 22401 16809 16566>,
			<13859 14010 18625 22531 17576 16626>,
			<14074 14358 19205 22736 19560 16896>,
			<14313 14626 19421 22727 20866 17544>,
			<14583 14783 19271 22517 21589 20104>,
			<14782 14934 19116 22195 21954 22320>,
			<14807 15226 19202 21743 21910 22288>,
			<14788 15883 19483 21060 21673 21780>,
			<14741 16344 19562 20256 21266 21465>,
			<14534 16390 18925 19164 20251 21318>,
			<14231 16305 17898 18180 19453 21247>,
			<13988 15927 16637 17772 20455 22411>,
			<13807 15300 15479 17543 21839 23962>,
			<13645 14658 15053 17161 19689 21462>,
			<13611 14122 14826 16887 16934 17943>,
			<13939 14195 15017 17301 17268 16287>,
			<14219 14158 14908 16951 17388 15514>,
			<14305 14044 14960 16882 16646 15123>,
			<14370 14303 14700 17310 16404 15040>,
			<15046 15056 15342 17576 16355 15025>,
			<15049 15260 15749 17696 17401 16121>,
			<14487 14687 15126 18044 17467 16407>,
			<14220 14363 15053 18960 18786 16829>,
			<13035 14274 15098 20621 22470 25019>,
			<13035 14274 15098 20621 22470 25019>,
			<13035 14274 15098 20621 22470 25019>;
	};

	qcom,pc-temp-y6-lut {
		qcom,lut-col-legend = <(-10) 0 10 25 40 50>;
		qcom,lut-row-legend = <10000 9800 9600 9400 9200 9000>,
			<8800 8600 8400 8200 8000 7800>,
			<7600 7400 7200 7000 6800 6600>,
			<6400 6200 6000 5800 5600 5400>,
			<5200 5000 4800 4600 4400 4200>,
			<4000 3800 3600 3400 3200 3000>,
			<2800 2600 2400 2200 2000 1800>,
			<1600 1400 1200 1000 900 800>,
			<700 600 500 400 300 200>,
			<100 0>;
		qcom,lut-data = <6292 5726 5316 5085 5021 5009>,
			<6257 5722 5318 5084 5021 5009>,
			<6223 5717 5319 5083 5020 5009>,
			<6191 5710 5319 5082 5020 5010>,
			<6162 5705 5318 5080 5020 5010>,
			<6136 5701 5317 5079 5020 5010>,
			<6110 5699 5312 5078 5020 5010>,
			<6088 5697 5304 5077 5020 5010>,
			<6074 5691 5300 5076 5020 5010>,
			<6062 5667 5298 5077 5021 5010>,
			<6056 5651 5297 5077 5022 5011>,
			<6068 5684 5302 5078 5023 5012>,
			<6089 5743 5311 5080 5025 5014>,
			<6077 5745 5312 5081 5027 5016>,
			<5954 5648 5303 5084 5029 5017>,
			<5857 5572 5292 5088 5032 5019>,
			<5857 5576 5287 5092 5036 5021>,
			<5862 5587 5282 5099 5040 5023>,
			<5862 5589 5275 5106 5045 5027>,
			<5849 5572 5266 5114 5054 5036>,
			<5836 5551 5255 5119 5059 5042>,
			<5834 5535 5238 5105 5048 5034>,
			<5834 5521 5219 5073 5026 5015>,
			<5835 5517 5209 5060 5016 5006>,
			<5846 5522 5206 5057 5012 5003>,
			<5863 5532 5203 5055 5011 5001>,
			<5879 5547 5198 5056 5011 5002>,
			<5896 5568 5192 5059 5012 5002>,
			<5915 5590 5191 5061 5014 5004>,
			<5935 5612 5196 5063 5017 5006>,
			<5956 5637 5204 5064 5020 5009>,
			<5978 5664 5214 5066 5025 5013>,
			<6000 5694 5230 5067 5029 5017>,
			<6023 5726 5246 5069 5030 5020>,
			<6047 5759 5266 5072 5029 5020>,
			<6071 5793 5287 5076 5027 5021>,
			<6096 5828 5311 5079 5024 5018>,
			<6120 5864 5338 5082 5021 5011>,
			<6145 5901 5365 5086 5020 5009>,
			<6168 5939 5393 5091 5023 5012>,
			<6194 5975 5421 5097 5026 5017>,
			<6227 6007 5451 5104 5028 5018>,
			<6269 6038 5483 5114 5029 5016>,
			<6318 6071 5521 5124 5026 5011>,
			<6380 6116 5568 5138 5027 5010>,
			<6424 6154 5602 5150 5039 5026>,
			<6442 6171 5600 5147 5047 5036>,
			<6483 6206 5637 5160 5057 5047>,
			<6548 6263 5682 5179 5068 5057>,
			<6619 6316 5734 5192 5072 5055>,
			<6689 6358 5779 5180 5046 5026>,
			<6778 6417 5836 5192 5044 5026>,
			<6911 6520 5963 5229 5055 5031>,
			<7378 6654 6136 5274 5074 5047>,
			<7378 6654 6136 5274 5074 5047>,
			<7378 6654 6136 5274 5074 5047>;
	};
};
